// * LIN description file
// * Target: MLX_Node
// * Project: Melexis Example LDF for LIN V2.0
// * Number:
// * File: Melexis_Example_LIN20.LDF
// * Author: H.Leutert
// * Company: Melexis GmbH
// * Version: V1.0
// * Date: 15/11/2012
LIN_description_file;
LIN_protocol_version = "2.0";
LIN_language_version = "2.0";
LIN_speed = 19.200 kbps;
Nodes {
Master: Master_Node, 5 ms, 0.100 ms;
Slaves: MLX_Node;
}

Signals {
   SigADCIntVS: 8, 0, MLX_Node,Master_Node;

   SigCommErr: 1, 0, MLX_Node,Master_Node;

   SigPWM_HV0_DutyCycle: 8, 0, Master_Node,MLX_Node;
   SigPWM_HV1_DutyCycle: 8, 0, Master_Node,MLX_Node;
   SigPWM_HV2_DutyCycle: 8, 0, Master_Node,MLX_Node;
   }

Frames {

MSG1 : 0x05, MLX_Node ,8 {
   SigCommErr,47;
   SigADCIntVS,48;
   }

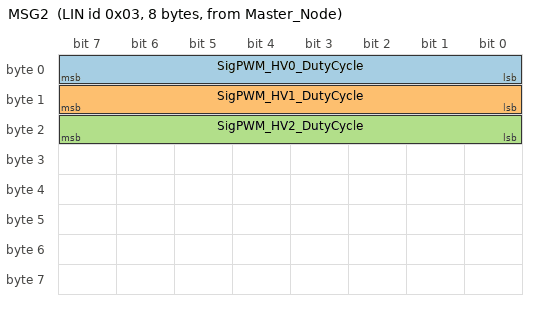
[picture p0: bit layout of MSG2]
MSG2 : 0x03, Master_Node ,8 {
   SigPWM_HV0_DutyCycle,0;
   SigPWM_HV1_DutyCycle,8;
   SigPWM_HV2_DutyCycle,16;
   }
}
Node_attributes {
       MLX_Node {
                LIN_protocol = "2.0";
                configured_NAD = 0x01;
                product_id = 0x0013, 0x0001, 0x01;
                response_error = SigCommErr;
                P2_min = 50 ms;
                ST_min = 20 ms;
                configurable_frames {
                        MSG1 = 0x1002;
                        MSG2 = 0x0003;
                }
        }
}
Schedule_tables {
  Normal_Schedule
    {
    MSG1 delay 20 ms;
    MSG2 delay 20 ms;
   }
  MRF_schedule {
    MasterReq delay 20 ms;
   }
  SRF_schedule {
    SlaveResp delay 20 ms;
   }
}
